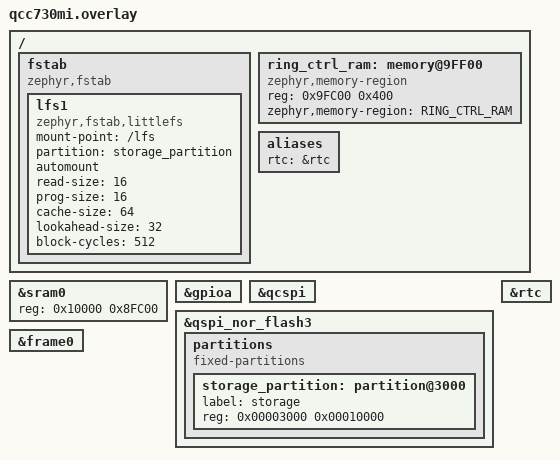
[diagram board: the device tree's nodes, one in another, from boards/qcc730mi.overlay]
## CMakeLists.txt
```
# Copyright (c) Qualcomm Technologies, Inc. and/or its subsidiaries.
# SPDX-License-Identifier: BSD-3-Clause-Clear

cmake_minimum_required(VERSION 3.20.0)
find_package(Zephyr REQUIRED HINTS $ENV{ZEPHYR_BASE})
project(qat_app)

file(GLOB app_sources src/main.c)
target_sources(app PRIVATE ${app_sources})

zephyr_linker_sources(SECTIONS http_server_sections.ld)


# ===== Post-build: run Python script for hex/strip/bin/hashed =====
find_package(Python3 COMPONENTS Interpreter REQUIRED)

set(POST_PY "${ZEPHYR_HAL_QCOM_MODULE_DIR}/tools/post_process.py")
set(HASH_SCRIPT "${ZEPHYR_HAL_QCOM_MODULE_DIR}/tools/qhash/sechash/createxbl.py")
set(SBL_TOOL_PREFIX "${ZEPHYR_SDK_INSTALL_DIR}/arm-zephyr-eabi/bin/arm-zephyr-eabi")

set(APP_OUT_DIR "${APPLICATION_BINARY_DIR}/zephyr")
set(HASHED_ELF_BASENAME "zephyr_HASHED.elf")
set(HASHED_ELF "${APP_OUT_DIR}/${HASHED_ELF_BASENAME}")

# Use add_custom_command for incremental build support
add_custom_command(
  OUTPUT "${HASHED_ELF}"
  COMMAND "${Python3_EXECUTABLE}" "${POST_PY}"
          --elf "${APPLICATION_BINARY_DIR}/zephyr/zephyr.elf"
          --tool-prefix "${SBL_TOOL_PREFIX}"
          --hash-script "${HASH_SCRIPT}"
          --hashed-out "${HASHED_ELF}"
          --check-noinit
  DEPENDS zephyr_final "${APPLICATION_BINARY_DIR}/zephyr/zephyr.elf"
  COMMENT "Post-process ELF and generate hashed ELF"
  VERBATIM
)

# Use zephyr_final target which is created by Zephyr build system
add_custom_target(post_process_elf ALL DEPENDS "${HASHED_ELF}")

# ===== Signing support: Manual target "sign" =====
# Usage: west build -b qcc730mi -t sign
# This allows signing without rebuilding/reconfiguring the project

# Paths to sectools
set(SECTOOLS_DIR "${ZEPHYR_HAL_QCOM_MODULE_DIR}/tools/sectools")
set(SECTOOLS_SCRIPT "${SECTOOLS_DIR}/sectools.py")
set(SECTOOLS_CONFIG "${ZEPHYR_HAL_QCOM_MODULE_DIR}/tools/sectools/config/qcc730/qcc730_secimage.xml")

# Input ELF files
set(SBL_ELF "${APPLICATION_BINARY_DIR}/modules/hal_qcom/qboot/${BOARD}_sbl.elf")
set(APP_ELF "${APPLICATION_BINARY_DIR}/zephyr/zephyr.elf")

# Output directories
set(SBL_SIGNED_DIR "${APPLICATION_BINARY_DIR}/modules/hal_qcom/qboot/zephyr_sec_sbl")
set(APP_SIGNED_DIR "${APPLICATION_BINARY_DIR}/zephyr/zephyr_sec_app")

# Output files (based on sectools output structure)
set(SBL_SIGNED_BIN "${SBL_SIGNED_DIR}/qcc730/sbl/${BOARD}_sbl.elf")
set(APP_SIGNED_BIN "${APP_SIGNED_DIR}/qcc730/app/zephyr.elf")

# Sign SBL image custom command
add_custom_command(
  OUTPUT "${SBL_SIGNED_BIN}"
  COMMAND "${Python3_EXECUTABLE}" "${SECTOOLS_SCRIPT}"
          secimage
          -i "${SBL_ELF}"
          -c "${SECTOOLS_CONFIG}"
          -sa
          -g sbl
          -o "${SBL_SIGNED_DIR}"
  WORKING_DIRECTORY "${SECTOOLS_DIR}"
  DEPENDS "${SBL_ELF}"
  COMMENT "Signing SBL image with sectools"
  VERBATIM
)

# Sign application image custom command
add_custom_command(
  OUTPUT "${APP_SIGNED_BIN}"
  COMMAND "${Python3_EXECUTABLE}" "${SECTOOLS_SCRIPT}"
          secimage
          -i "${APP_ELF}"
          -c "${SECTOOLS_CONFIG}"
          -sa
          -g app
          -o "${APP_SIGNED_DIR}"
  WORKING_DIRECTORY "${SECTOOLS_DIR}"
  DEPENDS "${APP_ELF}"
  COMMENT "Signing application image with sectools"
  VERBATIM
)

# Define "sign" target that triggers signing
# NOT added to ALL, so it won't run by default
add_custom_target(sign
  DEPENDS "${SBL_SIGNED_BIN}" "${APP_SIGNED_BIN}"
  COMMAND ${CMAKE_COMMAND} -E echo "========================================================================"
  COMMAND ${CMAKE_COMMAND} -E echo "? Signing completed successfully!"
  COMMAND ${CMAKE_COMMAND} -E echo "========================================================================"
  COMMAND ${CMAKE_COMMAND} -E echo "Signed SBL:         ${SBL_SIGNED_DIR}"
  COMMAND ${CMAKE_COMMAND} -E echo "Signed Application: ${APP_SIGNED_DIR}"
  COMMAND ${CMAKE_COMMAND} -E echo "========================================================================"
  VERBATIM
)

# Ensure signing depends on ELF generation (if running in same build)
add_dependencies(sign post_process_elf)
```

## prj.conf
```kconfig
# Copyright (c) Qualcomm Technologies, Inc. and/or its subsidiaries.
# SPDX-License-Identifier: BSD-3-Clause-Clear

# nothing here

CONFIG_NETWORKING=y
CONFIG_NET_IPV4=y
CONFIG_NET_IPV6=y

# ============================================
# IPv6 ND / RS / RA / DAD (for SLAAC autoconf)
# ============================================
# (Most are default-y when NET_IPV6 is enabled, but set explicitly for clarity)
CONFIG_NET_IPV6_NBR_CACHE=y
CONFIG_NET_IPV6_ND=y
CONFIG_NET_IPV6_DAD=y
CONFIG_NET_IPV6_RS_TIMEOUT=1
CONFIG_NET_INITIAL_HOP_LIMIT=64

# If you want DNS server info from Router Advertisement (RDNSS)
CONFIG_NET_IPV6_RA_RDNSS=y
CONFIG_NET_TCP=y
CONFIG_NET_UDP=y
CONFIG_NET_SOCKETS=y
CONFIG_DNS_RESOLVER=y
# Replace existing DHCP/RA DNS entries when DNS is manually reconfigured.
CONFIG_DNS_RECONFIGURE_CLEANUP=y
CONFIG_NET_MGMT=y
CONFIG_NET_CONFIG_AUTO_INIT=n
CONFIG_ETH_DRIVER=n
CONFIG_TEST_RANDOM_GENERATOR=y
CONFIG_NET_L2_ETHERNET=y
CONFIG_NET_SHELL=y
# eventfd slots are a compile-time static pool; each user holds one for its
# whole lifetime. Current users:
#   1) net socket service thread   (boot, never freed) - DHCPv4 srv/DNS/SNTP/zperf
#   2) qcom hostap eloop thread    (boot, never freed) - pulled in by
#      CONFIG_WIFI_QCOM_WPS -> select WIFI_QCOM_HOSTAP_ELOOP
#   3) HTTP server                 (AT+WEBSERVER=1, freed on stop)
# 2 was enough before WPS existed; with the eloop thread the pool was full at
# boot and http_server_init() looped forever on eventfd failed (-12).
# 8 matches the upstream "default 8 if WIFI_NM_WPA_SUPPLICANT" and leaves room
# for NAN USD / P2P, which select the same eloop.
CONFIG_ZVFS_EVENTFD_MAX=8
CONFIG_NET_MAX_CONTEXTS=16
# dhcp
CONFIG_NET_DHCPV4=y
CONFIG_NET_DHCPV4_SERVER=y
CONFIG_WIFI_QCOM_AUTO_DHCPV4=y
CONFIG_NET_DHCPV4_INITIAL_DELAY_MAX=2

CONFIG_WIFI=y
CONFIG_WIFI_QCOM=y
CONFIG_NET_L2_WIFI_SHELL=y
CONFIG_NET_MGMT_EVENT_QUEUE_TIMEOUT=5000
CONFIG_NET_MGMT_EVENT_QUEUE_SIZE=16
CONFIG_NET_L2_WIFI_MGMT=y

CONFIG_NET_LOG=y
CONFIG_NET_L2_ETHERNET_LOG_LEVEL_DBG=n
CONFIG_NET_L2_WIFI_MGMT_LOG_LEVEL_DBG=y
CONFIG_NET_MGMT_EVENT_LOG_LEVEL_DBG=n
CONFIG_WIFI_LOG_LEVEL_DBG=y

# increase CONFIG_NET_BUF_DATA_SIZE to 512, allow more net buffer allocated.
CONFIG_NET_BUF_DATA_SIZE=512
CONFIG_NET_MGMT_EVENT_STACK_SIZE=3072
# increase SYSTEM_WORKQUEUE_STACK_SIZE to 2048, fix potential stack overflow issues.
CONFIG_SYSTEM_WORKQUEUE_STACK_SIZE=2048

# zperf
CONFIG_NET_ZPERF=y
CONFIG_NET_ZPERF_SERVER=y
# allow more ZVFS_POLL (increased to 32 for HTTP server)
CONFIG_ZVFS_POLL_MAX=32

#power
CONFIG_PM=y
CONFIG_STATS=n
CONFIG_PM_STATS=y

# counter driver.
CONFIG_COUNTER=y

# RTC driver
CONFIG_RTC=y
CONFIG_RTC_QCC730=y
# RTC shell
CONFIG_RTC_SHELL=y

CONFIG_WIFI_TSF_RTC_CORRECTION=y

# avoid stack overflow in the idle task thread.
CONFIG_IDLE_STACK_SIZE=1024

# enable SEGGER RTT
#CONFIG_UART_CONSOLE=n
#CONFIG_RTT_CONSOLE=y
#CONFIG_USE_SEGGER_RTT=y
#CONFIG_SHELL_BACKEND_SERIAL=n
#CONFIG_SHELL_BACKEND_RTT=y

# Crash dump configuration of two backend options:
# 1) Logging backend:
#    # CONFIG_DEBUG_COREDUMP=y
#    # CONFIG_DEBUG_COREDUMP_BACKEND_LOGGING=y
# 2) Flash partition backend:
#    # CONFIG_DEBUG_COREDUMP=y
#    # CONFIG_DEBUG_COREDUMP_BACKEND_FLASH_PARTITION=y
#    # CONFIG_DEBUG_COREDUMP_SHELL=y
#    # CONFIG_FLASH=y
#    # CONFIG_FLASH_MAP=y
#    # CONFIG_FLASH_PAGE_LAYOUT=y

CONFIG_NET_ZPERF_MAX_PACKET_SIZE=1500

CONFIG_FLASH=y
CONFIG_FLASH_QCC730=y
CONFIG_BOARD_QCC730_UART_GPIO_OPTION=1
CONFIG_PM_DEVICE=y

CONFIG_GPIO=y
CONFIG_GPIO_SHELL=y

# qcrypto is required: libwifiqcc730.a depends on nt_prng_init/nt_wlan_hw_prng_get.
# --allow-multiple-definition lets the ALT symbols coexist with MBEDTLS_BUILTIN.
CONFIG_QCRYPTO=y
CONFIG_MBEDTLS=y
# CONFIG_MBEDTLS_BUILTIN selects the built-in mbedTLS implementation with full
# X.509/PEM certificate parsing support. Without it, cert parsing fails with
# MBEDTLS_ERR_X509_INVALID_FORMAT (-0x2180). CONFIG_MBEDTLS_TEST is a minimal
# test-only config that lacks complete X.509 support.
CONFIG_MBEDTLS_BUILTIN=y
CONFIG_REQUIRES_FULL_LIBC=y
CONFIG_MBEDTLS_ASN1_PARSE_C=y
CONFIG_MBEDTLS_PEM_CERTIFICATE_FORMAT=y

CONFIG_CODE_DATA_RELOCATION=y
CONFIG_DP_RAM_LOCATED=y

CONFIG_NET_PKT_TX_COUNT=20
CONFIG_NET_PKT_RX_COUNT=20
CONFIG_NET_BUF_TX_COUNT=20
CONFIG_NET_BUF_RX_COUNT=20
CONFIG_NET_BUF_DATA_SIZE=1500
CONFIG_NET_TCP_MAX_SEND_WINDOW_SIZE=20000
CONFIG_SYS_HEAP_RUNTIME_STATS=y
CONFIG_NET_BUF_POOL_USAGE=y

# Optimize for speed - required for WiFi throughput performance
# Note: Increases 50KB code size, verified to fit within QCC730 constraints
CONFIG_SPEED_OPTIMIZATIONS=y



# ============================================
# MCUmgr Configuration (disabled)
# ============================================
# ZCBOR - required for MCUmgr
# CONFIG_ZCBOR=y
# CONFIG_ZCBOR_CANONICAL=y

# MCUmgr Core - basic MCUmgr support
# CONFIG_MCUMGR=y

# ============================================
# Qualcomm Image Management (disabled)
# ============================================
# CONFIG_QCOM_IMG_MGMT=y
# CONFIG_QCOM_IMG_MGMT_LOG_LEVEL_INF=y
# CONFIG_QCOM_IMG_MGMT_ZCBOR_MAX_STR_LEN=1024
# CONFIG_QCOM_IMG_MGMT_UDP_PORT=1337
# CONFIG_QCOM_IMG_MGMT_UDP_MTU=1500
# CONFIG_QCOM_IMG_MGMT_NETBUF_COUNT=4
# CONFIG_QCOM_IMG_MGMT_NETBUF_SIZE=4096
# CONFIG_QCOM_IMG_MGMT_SHA256_SUPPORT=y

# ============================================
# Qualcomm Watchdog Config
# ============================================
# Always enabled to ensure watchdog code is compiled
CONFIG_WATCHDOG=y
# Enable watchdog functionality
# CONFIG_QWDT=y
# CONFIG_WATCH_DOG_BITE_TIME=8

# Enable runtime NMI for watchdog bark handling
# CONFIG_RUNTIME_NMI=y

# secure storage configuration
#CONFIG_MBEDTLS_PSA_CRYPTO_C=y
#CONFIG_SECURE_STORAGE=y
#CONFIG_SECURE_STORAGE_ITS_IMPLEMENTATION_ZEPHYR=y
#CONFIG_SECURE_STORAGE_ITS_STORE_MODULE=y
#CONFIG_SECURE_STORAGE_ITS_TRANSFORM_AEAD_SCHEME_CUSTOM=y
#CONFIG_SECURE_STORAGE_ITS_TRANSFORM_AEAD_KEY_PROVIDER_CUSTOM=y
#CONFIG_ZMS=y
#CONFIG_SECURE_STORAGE_ITS_STORE_IMPLEMENTATION_ZMS=y
#CONFIG_PSA_WANT_ALG_CCM=y
#CONFIG_PSA_WANT_KEY_TYPE_AES=y
#CONFIG_SECURE_STORAGE_ITS_MAX_DATA_SIZE=2000

# two wifi drv iface support
CONFIG_WIFI_NM=y
CONFIG_NET_IF_MAX_IPV6_COUNT=2
CONFIG_NET_IF_MAX_IPV4_COUNT=2
CONFIG_NET_IF_MCAST_IPV6_ADDR_COUNT=4

# ============================================
# Qualcomm AT Config
# ============================================

# enable RING_SERVICE
CONFIG_RING_SERVICE=y

# Enable libcat
CONFIG_CAT=y

# Enable QAT
CONFIG_QAT=y
CONFIG_QAT_SERVICE_STACK_SIZE=8192

# Enable QAT COMMON COMMAND
CONFIG_QAT_COMMON=y
CONFIG_QAT_WLAN=y

# HTTP client AT commands
CONFIG_QAT_HTTPC=y
# ============================================
# OTA AT Commands
# ============================================
CONFIG_QAT_OTA=y

# Enable MQTT client AT feature
CONFIG_MQTT_LIB=y
CONFIG_MQTT_LIB_TLS=y
CONFIG_MQTTC_AT=y
CONFIG_QAT_MQTTC=y
# Increase TCP workqueue stack (default 1024 overflows into rx_stack during MQTT QoS1)
# Root cause: work_q_stack at 0x45e08 grows into rx_stack at 0x45708 -> EXC_RETURN corruption
CONFIG_NET_TCP_WORKQ_STACK_SIZE=2048
# Increase rx_q[0] stack for TCP+MQTT processing (default 1792 is too small)
CONFIG_NET_RX_STACK_SIZE=4096
# Increase max TCP connections: 2 MQTT sessions + DNS + ring = 4 minimum, use 8 for margin
CONFIG_NET_MAX_CONN=8
# Increase recv_thread stack: hex_buf[2001] + payload_buf[1001] = 3002 bytes on stack overflows 2048 default
CONFIG_MQTTC_AT_RECV_THREAD_STACK_SIZE=4096
CONFIG_DYNAMIC_THREAD=y
CONFIG_DYNAMIC_THREAD_ALLOC=y

# HTTPC AT TLS / certificate loading prerequisites
CONFIG_TLS_CREDENTIALS=y
CONFIG_NET_SOCKETS_SOCKOPT_TLS=y
CONFIG_FILE_SYSTEM=y
CONFIG_FILE_SYSTEM_LITTLEFS=y
CONFIG_FLASH_MAP=y

# TLS record buffer: default inherits NET_BUF_DATA_SIZE=1500 which is too small
# for the TLS handshake. The server Certificate message can exceed 1500 bytes,
# causing MBEDTLS_ERR_SSL_BUFFER_TOO_SMALL. Zephyr's tls_mbedtls_handshake()
# maps all unhandled mbedTLS errors to ENOMEM, so zsock_connect() returns -12.
# 4096 bytes is sufficient for typical server certificate chains.
CONFIG_MBEDTLS_SSL_MAX_CONTENT_LEN=4096

# HTTP Server for WiFi provisioning (AT+WEBSERVER)
CONFIG_FDTABLE=y
CONFIG_HTTP_SERVER=y
CONFIG_QAT_HTTPSERVER=y
# Dual-stack: 4 services (HTTP IPv4/v6 + HTTPS IPv4/v6)
CONFIG_HTTP_SERVER_NUM_SERVICES=4
# Limit to 1 concurrent HTTPS client: each TLS context needs ~8KB heap
# (2 x MBEDTLS_SSL_MAX_CONTENT_LEN=4096). Browser sends 4-6 parallel
# connections which exhausts the ~42KB free RAM. 1 client is sufficient
# for the provisioning use case.
CONFIG_HTTP_SERVER_MAX_CLIENTS=1
# Reduce TIME-WAIT duration (default 1500ms) so connections clear faster.
CONFIG_NET_TCP_TIME_WAIT_DELAY=250
# Increase TCP connection pool to handle residual connections during HTTPS testing.
CONFIG_NET_MAX_CONN=24
# HTTPS server needs 2 TLS contexts: 1 listen socket + 1 client connection.
CONFIG_NET_SOCKETS_TLS_MAX_CONTEXTS=3

# ============================================
# mbedTLS debug: enable ECDHE-RSA and debug log for B4 mutual-auth diagnosis
# ============================================
CONFIG_MBEDTLS_KEY_EXCHANGE_ECDHE_RSA_ENABLED=y
# Enable ECDHE-ECDSA for ECDSA-signed certificates
CONFIG_MBEDTLS_KEY_EXCHANGE_ECDHE_ECDSA_ENABLED=y
# ECC support required to parse ECDSA CA/server certificates
CONFIG_MBEDTLS_ECP_C=y
CONFIG_MBEDTLS_ECDH_C=y
CONFIG_MBEDTLS_ECDSA_C=y
CONFIG_MBEDTLS_ECP_DP_SECP256R1_ENABLED=y
CONFIG_MBEDTLS_LOG_LEVEL_DBG=y
CONFIG_HTTPC_AT_LOG_LEVEL=4

# Increase TLS handshake timeout: default 3s is too short for RSA mutual-auth
# on software mbedTLS (no HW crypto). 30s gives enough margin.
CONFIG_NET_SOCKETS_CONNECT_TIMEOUT=30000

CONFIG_RING0_DESC_COUNT=8
CONFIG_RING0_BUF_SIZE=1400
# at demo unuse ring1 and ring 2, decrease count to save memory
CONFIG_RING1_DESC_COUNT=2
CONFIG_RING1_BUF_SIZE=64
CONFIG_RING2_DESC_COUNT=2
CONFIG_RING2_BUF_SIZE=64
# ============================================
# DNS Resolver
# ============================================
CONFIG_DNS_RESOLVER=y
# Allow A + AAAA to be in-flight simultaneously (gethostbyname2 v4v6/v6v4)
CONFIG_DNS_NUM_CONCUR_QUERIES=2

# ============================================
# SNTP Client
# ============================================
CONFIG_SNTP=y

# file store and WiFi credential persistence
CONFIG_QAT_FSTORE=y
CONFIG_QAT_WIFI_CRED=y

# ============================================
# WPS PBC Enrollee
# ============================================
# Automatically selects: WIFI_NM_WPA_SUPPLICANT, WIFI_NM_WPA_SUPPLICANT_MINIMAL,
#                        WIFI_QCOM_HOSTAP_ELOOP
# CRYPTO_ALT must be set explicitly: MINIMAL=y forces choice default to CRYPTO_NONE,
# but WPS requires mbedtls crypto — override it here.
CONFIG_WIFI_QCOM_WPS=y
CONFIG_WIFI_NM_WPA_SUPPLICANT_CRYPTO_ALT=y
```

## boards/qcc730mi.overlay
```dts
/*
 * Copyright (c) Qualcomm Technologies, Inc. and/or its subsidiaries.
 *
 * SPDX-License-Identifier: BSD-3-Clause-Clear
 */

/ {
	fstab {
		compatible = "zephyr,fstab";
		lfs1: lfs1 {
			compatible = "zephyr,fstab,littlefs";
			mount-point = "/lfs";
			partition = <&storage_partition>;
			automount;
			read-size = <16>;
			prog-size = <16>;
			cache-size = <64>;
			lookahead-size = <32>;
			block-cycles = <512>;
		};
	};

	ring_ctrl_ram: memory@9FF00 {
		compatible = "zephyr,memory-region", "mmio-sram";
		reg = <0x9FC00 0x400>;
		zephyr,memory-region = "RING_CTRL_RAM";
	};

	aliases {
		rtc = &rtc;
	};
};

/* 0x9FF00~0xA0000 are reserved as ring buffer control block */
&sram0 {
	reg = <0x10000 0x8FC00>;
};

&gpioa {
	status = "okay";
};

&qcspi {
	status = "okay";
};

&qspi_nor_flash3 {
	partitions {
		compatible = "fixed-partitions";
		#address-cells = <1>;
		#size-cells = <1>;

		storage_partition: partition@3000 {
			label = "storage";
			/* Starts at 12KB offset to protect the FDT, size is 64KB. */
			reg = <0x00003000 0x00010000>;
		};
	};
};

&frame0 {
	status = "okay";
};

&rtc {
	status = "okay";
};
```

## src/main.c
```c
/*
 * Copyright (c) Qualcomm Technologies, Inc. and/or its subsidiaries.
 *
 * SPDX-License-Identifier: BSD-3-Clause-Clear
 */

#include <zephyr/shell/shell.h>
#include <zephyr/sys/util.h>
#include <stdio.h>
#include <stdlib.h>
#include <stdbool.h>

#include <zephyr/kernel.h>
#include <zephyr/logging/log.h>

LOG_MODULE_REGISTER(app, LOG_LEVEL_INF);

int main(void)
{
    printf("Hello World! %s\n", CONFIG_BOARD_TARGET);
    return 0;
}
```
